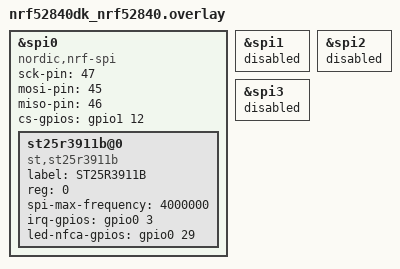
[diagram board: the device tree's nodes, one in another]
&spi0 {
	compatible = "nordic,nrf-spi";
	status = "okay";
	sck-pin = <47>;
	mosi-pin = <45>;
	miso-pin = <46>;
	cs-gpios = <&gpio1 12 0>;

	st25r3911b@0 {
		label = "ST25R3911B";
		compatible = "st,st25r3911b";
		reg = <0>;
		spi-max-frequency = <4000000>;
		irq-gpios = <&gpio0 3 0>;
		led-nfca-gpios = <&gpio0 29 0>;
	};
};

&spi1 {
	status = "disabled";
};

&spi2 {
	status = "disabled";
};

&spi3 {
	status = "disabled";
};
